# STM32MP21_CA35 register map
File version: 0.4
CPU: CM33 r0p1, little endian, MPU, FPU, vendor SysTick, 8 interrupt priority bits
Registers are 32-bit, read-write, reset 0x0 unless marked. A register's access mark holds for its fields unless they carry their own. Offsets are from the block's base; [hi:lo] are bit positions; {n}, {i} and the like mark numbered series.

## RISAB1 — RISAB1 register block
Base 0x420F0000
Same registers: RISAB1_S 0x520F0000
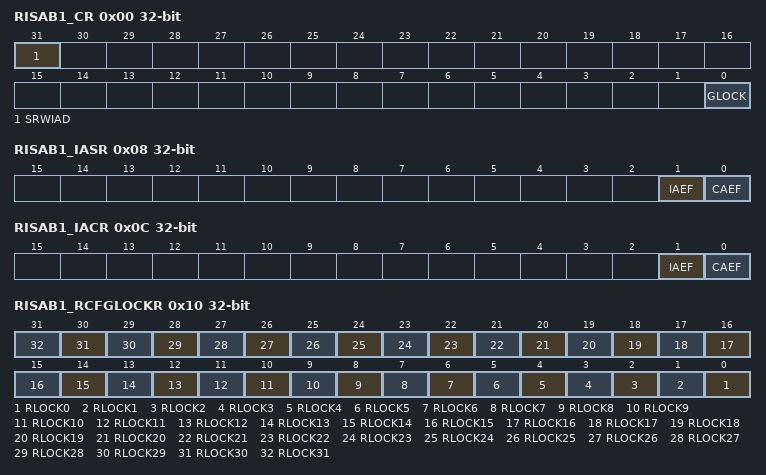
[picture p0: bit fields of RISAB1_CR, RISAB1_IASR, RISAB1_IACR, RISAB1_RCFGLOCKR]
0x00 RISAB1_CR — RISAB configuration register
  [31] SRWIAD — Secure read/write illegal access disable
    0=Any secure access to non-secure blocks or pages is illegal; 1=Secure read/write data access is allowed to non-secure blocks or pages, while secure execute generates a bus error
  [0] GLOCK — Global lock
    0=RISAB registers are writable; 1=All writes to RISAB registers are ignored, except RISAB_IACR
0x08 RISAB1_IASR ro — RISAB illegal access status register
  [1] IAEF — Illegal access error flag
  [0] CAEF — configuration access error flag
0x0C RISAB1_IACR wo — RISAB illegal access clear register
  [1] IAEF — Illegal access error flag
  [0] CAEF — Configuration access error flag
0x10 RISAB1_RCFGLOCKR — RISAB configuration lock register
  [all] fields
    0=RISAB_PGy_CIDCFGR, RISAB_PGy_SECCFGR, RISAB_PGy_PRIVCFGR, and RISAB_PGy_C2PRIVCFGR are writable; 1=Writes to RISAB_PGy_CIDCFGR, RISAB_PGy_SECCFGR, RISAB_PGy_PRIVCFGR, and RISAB_PGy_C2PRIVCFGR are ignored
  [n] RLOCK{n} (n=0..31) — Resource lock for page y
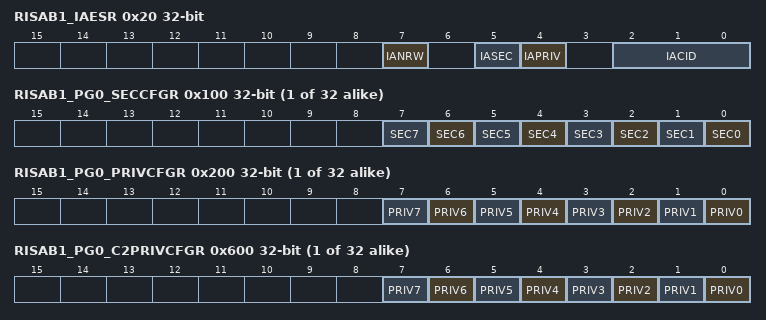
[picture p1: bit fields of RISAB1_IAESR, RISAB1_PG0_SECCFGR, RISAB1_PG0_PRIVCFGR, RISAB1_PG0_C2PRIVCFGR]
0x20 RISAB1_IAESR ro — RISAB illegal access error status register
  [7] IANRW — Illegal access read/write
    0=Illegal access was a data read; 1=Illegal access was a data write
  [5] IASEC — Illegal access security
    0=Illegal access was non-secure; 1=Illegal access was secure
  [4] IAPRIV — Illegal access privileged
    0=Illegal access was unprivileged; 1=Illegal access was privileged
  [2:0] IACID — illegal access compartment ID
0x24 RISAB1_IADDR ro — RISAB illegal address register
  [31:0] IADD — Illegal address
{0x100+4i} RISAB1_PG{i}_SECCFGR (reset mask 0xFFFFFF00) (i=0..31) — RISAB page {i} security configuration register
  [all] fields
    0=Only non-secure requests can access block z of page y; 1=Only secure requests can access block z of page y
  [n] SEC{n} (n=0..7) — Security configuration for block z
{0x200+4i} RISAB1_PG{i}_PRIVCFGR (i=0..31) — RISAB page {i} default privileged configuration register
  [all] fields
    0=Privileged and unprivileged access are granted to block z of page y; 1=Only privileged access is granted to block z of page y
  [n] PRIV{n} (n=0..7) — Privileged configuration for block z
{0x600+4i} RISAB1_PG{i}_C2PRIVCFGR (i=0..31) — RISAB page {i} privileged configuration register for compartment 2
  [all] fields
    0=Compartment 2 privileged and unprivileged accesses are granted to block z of page y, if PRIVy is cleared in RISAB_CID2PRIVCFGR; 1=Only compartment 2 privileged access is granted to block z of page y
  [n] PRIV{n} (n=0..7) — Privileged configuration for block z
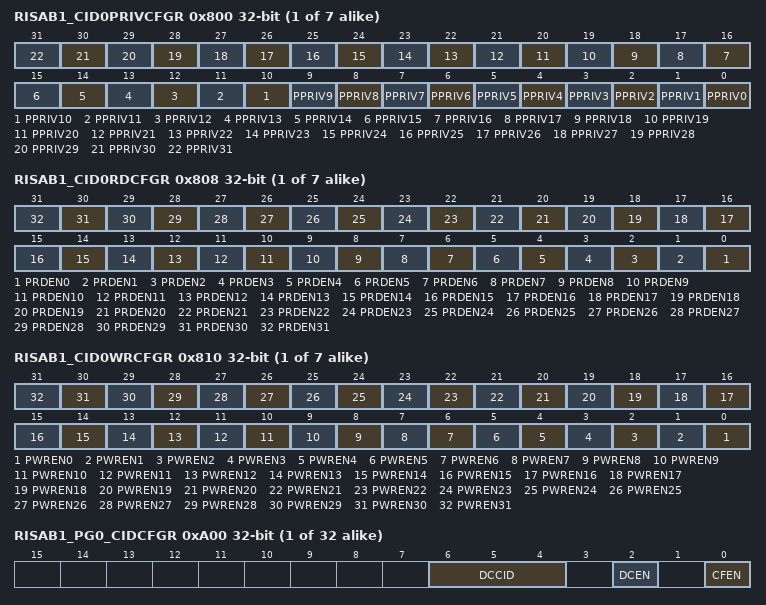
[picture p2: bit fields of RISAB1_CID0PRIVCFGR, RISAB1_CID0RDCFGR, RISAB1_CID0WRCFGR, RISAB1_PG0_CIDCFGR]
{0x800+0x20*i} RISAB1_CID{i}PRIVCFGR (i=0..6) — RISAB compartment {i} privilege configuration register
  [all] fields
    0=Privileged and unprivileged access for compartment x are granted to page y; 1=Compartment x unprivileged accesses to page y are blocked (read as 0, write is ignored)
  [n] PPRIV{n} (n=0..31) — Page y privileged configuration (y=31 to 0)
{0x808+0x20*i} RISAB1_CID{i}RDCFGR (i=0..6) — RISAB compartment {i} read configuration register
  [all] fields
    0=Compartment x read as 0 when accessing page y; 1=Compartment x can read page y
  [n] PRDEN{n} (n=0..31) — Page y read access enable (y=31 to 0)
{0x810+0x20*i} RISAB1_CID{i}WRCFGR (i=0..6) — RISAB compartment {i} write configuration register
  [all] fields
    0=Compartment x write to page y is ignored; 1=Compartment x can write page y
  [n] PWREN{n} (n=0..31) — Page y write access enable (y=31 to 0)
{0xA00+4i} RISAB1_PG{i}_CIDCFGR (i=0..31) — RISAB page {i} CID configuration register
  [6:4] DCCID — Delegated configuration CID
  [2] DCEN — Delegated configuration enable
    0=Bit/register can be written only by trusted domain application; 1=Bit/register can be written only by the compartment DCCID[2:0], defined in this register
  [0] CFEN — CID filtering enable
    0=Compartment-based filtering is disabled for page y; 1=Compartment-based filtering is enabled for page y
0xFE8 RISAB1_HWCFGR3 ro — RISAB hardware configuration register 3
  [31:0] CFG — Hardware configuration
0xFEC RISAB1_HWCFGR2 ro reset 0x20000 (reset mask 0xFFF0FFFF) — RISAB hardware configuration register 2
  [31:0] CFG — Hardware configuration
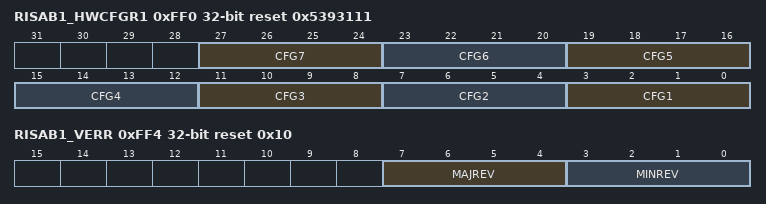
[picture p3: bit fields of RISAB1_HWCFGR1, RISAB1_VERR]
0xFF0 RISAB1_HWCFGR1 ro reset 0x5393111 (reset mask 0xF0FFFFFF) — RISAB hardware configuration register 1
  [4n-1:4n-4] CFG{n} (n=1..7) — Hardware configuration {n}
0xFF4 RISAB1_VERR ro reset 0x10 — RISAB version register
  [7:4] MAJREV — RISAB major revision
  [3:0] MINREV — RISAB minor revision
0xFF8 RISAB1_IPIDR ro reset 0x100160 (reset mask 0xFFFFFFF0) — RISAB identification register
  [31:0] ID — RISAB identification code
0xFFC RISAB1_SIDR ro reset 0xA3C5DD04 — RISAB size identification register
  [31:0] SID — RISAB size identification code

## RISAB2 — RISAB2 register block
Base 0x42100000
Same registers: RISAB2_S 0x52100000
Registers as RISAB1 (with RISAB1 read as RISAB2).

## RISAB3 — RISAB3 register block
Base 0x42110000
Same registers: RISAB3_S 0x52110000
Registers as RISAB1 (with RISAB1 read as RISAB3); these are added or differ:
0xFEC RISAB3_HWCFGR2 ro reset 0x10000 (reset mask 0xFFF0FFFF) — RISAB hardware configuration register 2
  [31:0] CFG — Hardware configuration

## RISAB5 — RISAB5 register block
Base 0x42130000
Same registers: RISAB5_S 0x52130000
Registers as RISAB1 (with RISAB1 read as RISAB5).
